AUTOSAR XML (schema 4-0-3)
package /CalibrationComponents
  parameter sw component type SOCR: data-type-mapping=[SOCR_CodeDataTypeMappingsSet, WorkingDataTypeMappingsSet]
    provide port SOCR_Pport: provided-interface=SOCR_if
      provided-com-specs:
        init-value=SOCR_Pport_KaSOCR_Ah_OvrdValue_CellCapacityCharge:96 x 55, parameter=KaSOCR_Ah_OvrdValue_CellCapacityCharge
        init-value=SOCR_Pport_KaSOCR_Ah_OvrdValue_CellCapacityDischarge:96 x 55, parameter=KaSOCR_Ah_OvrdValue_CellCapacityDischarge
        init-value=SOCR_Pport_KaSOCR_Pct_OvrdValue_CellSOCArray_new:96 x 100, parameter=KaSOCR_Pct_OvrdValue_CellSOCArray_new
        init-value=SOCR_Pport_KaSOCR_Pct_SOCini:96 x 95, parameter=KaSOCR_Pct_SOCini
        init-value=55, parameter=KeSOCR_Ah_BatteryCellsCap
        init-value=0, parameter=KeSOCR_Ah_MinCellCapacityCharge_Val
        init-value=0, parameter=KeSOCR_Ah_MinCellCapacityDischarge_Val
        init-value=55, parameter=KeSOCR_Ah_OvrdValue_BatteryPackCapacity
        init-value=55, parameter=KeSOCR_Ah_PackCapacityCharge_MaxVal
        init-value=55, parameter=KeSOCR_Ah_PackCapacityCharge_Val
        init-value=0, parameter=KeSOCR_Ah_PackCapacityCharge_minVal
        init-value=55, parameter=KeSOCR_Ah_PackCapacityDischarge_MaxVal
        init-value=55, parameter=KeSOCR_Ah_PackCapacityDischarge_Val
        init-value=0, parameter=KeSOCR_Ah_PackCapacityDischarge_minVal
        init-value=1, parameter=KeSOCR_Cnt_NumberOfCellParal
        init-value=0.019999999552965164, parameter=KeSOCR_I_CoseToZero
        init-value=0, parameter=KeSOCR_I_CoulombsCSC
        init-value=16.299999237060547, parameter=KeSOCR_I_CurrForCalcTTC_NoCharge
        init-value=3, parameter=KeSOCR_I_LowCurrent
        init-value=1, parameter=KeSOCR_I_SOCFixLowCurrent
        init-value=1, parameter=KeSOCR_I_ThrshldCorrSOCConvrg
        init-value=2, parameter=KeSOCR_I_ThrshldLowCurrent
        init-value=1, parameter=KeSOCR_I_ThrshldSOCCorrection_DE
        init-value=0.20000000298023224, parameter=KeSOCR_I_ThrshldZeroCurrent
        init-value=2, parameter=KeSOCR_Pct_AC_ChgPctCoeff
        init-value=0.10000000149011612, parameter=KeSOCR_Pct_CloseToZeroThreshold
        init-value=0, parameter=KeSOCR_Pct_CorrectedPackSOC_Val
        init-value=95, parameter=KeSOCR_Pct_CorrectedPackSOC_ini
        init-value=95.05000305175781, parameter=KeSOCR_Pct_CorrectedScaledSOC_ToCAN
        init-value=100.05000305175781, parameter=KeSOCR_Pct_CustomerPackSOC_MaxVal
        init-value=0, parameter=KeSOCR_Pct_CustomerPackSOC_Val
        init-value=0, parameter=KeSOCR_Pct_CustomerPackSOC_minVal
        init-value=100.05000305175781, parameter=KeSOCR_Pct_CustomerRealScaledSOC_ToCAN
        init-value=0, parameter=KeSOCR_Pct_DispSOC_Val
        init-value=95.05000305175781, parameter=KeSOCR_Pct_DisplayPackSOC_MaxVal
        init-value=95, parameter=KeSOCR_Pct_DisplayPackSOC_ini
        init-value=0, parameter=KeSOCR_Pct_DisplayPackSOC_minVal
        init-value=21.200000762939453, parameter=KeSOCR_Pct_LowSOC1_Reset
        init-value=20, parameter=KeSOCR_Pct_LowSOC1_Set
        init-value=16, parameter=KeSOCR_Pct_LowSOC2_Reset
        init-value=15, parameter=KeSOCR_Pct_LowSOC2_Set
        init-value=10, parameter=KeSOCR_Pct_LowSOC3_Reset
        init-value=8, parameter=KeSOCR_Pct_LowSOC3_Set
        init-value=0.6149818301200867, parameter=KeSOCR_Pct_MaxBalDrain
        init-value=94.9000015258789, parameter=KeSOCR_Pct_MaxSOCBeforeVCU_ChrgComplete
        init-value=0.01729624904692173, parameter=KeSOCR_Pct_MaxSlewRateLimitPer100msCorrSOC
        init-value=100, parameter=KeSOCR_Pct_OvrdValue_BatteryPackSOC
        init-value=100, parameter=KeSOCR_Pct_OvrdValue_DisplayPackSOC
        init-value=100, parameter=KeSOCR_Pct_OvrdValue_MaxSOC
        init-value=0, parameter=KeSOCR_Pct_OvrdValue_MinSOC
        init-value=0, parameter=KeSOCR_Pct_PackSOCDiff_Val
        init-value=0, parameter=KeSOCR_Pct_PackSOCDiff_ini
        init-value=1, parameter=KeSOCR_Pct_SOCChangeThreshold
        init-value=5, parameter=KeSOCR_Pct_SOCJumpWarn_Reset
        init-value=5, parameter=KeSOCR_Pct_SOCJumpWarn_Set
        init-value=95.05000305175781, parameter=KeSOCR_Pct_SOCOverWarn_Reset
        init-value=96, parameter=KeSOCR_Pct_SOCOverWarn_Set
        init-value=50, parameter=KeSOCR_Pct_SOC_SetPointUDS31010F15
        init-value=93, parameter=KeSOCR_Pct_SOC_ThresholdTTC
        init-value=2, parameter=KeSOCR_Pct_SlewRateLimitFbackDriving
        init-value=0.0016666667070239782, parameter=KeSOCR_Pct_SlewRateLimitPer100msAC
        init-value=0.008648124523460865, parameter=KeSOCR_Pct_SlewRateLimitPer100msCorrSOC
        init-value=0.0047222222201526165, parameter=KeSOCR_Pct_SlewRateLimitPer100msDC
        init-value=0.008648124523460865, parameter=KeSOCR_Pct_SlewRateLimitPer100msDriving
        init-value=30, parameter=KeSOCR_Pct_ThrshldCorrSOC
        init-value=0, parameter=KeSOCR_Pct_TsigBatteryPackSOC_Val
        init-value=37.5, parameter=KeSOCR_R_CSCBalancingR
        init-value=18, parameter=KeSOCR_T_HighTemprChgEnd_DC
        init-value=4.25, parameter=KeSOCR_U_100PctVoltage
        init-value=4.171000003814697, parameter=KeSOCR_U_CloseToEndOfCharge_AC
        init-value=4.184999942779541, parameter=KeSOCR_U_CloseToEndOfCharge_DC_1
        init-value=4.215000152587891, parameter=KeSOCR_U_CloseToEndOfCharge_DC_2
        init-value=4.179999828338623, parameter=KeSOCR_U_FullSOCVoltage_Reset
        init-value=4.179999828338623, parameter=KeSOCR_U_FullSOCVoltage_Set
        init-value=4.17549991607666, parameter=KeSOCR_U_TTC_StrategyThrshld
        init-value=1, parameter=KeSOCR_k_AccelCoeffAC_ChgSteadySt
        init-value=-8, parameter=KeSOCR_k_Coeff1_AC
        init-value=-5.714285850524902, parameter=KeSOCR_k_Coeff1_DC
        init-value=1.7999999523162842, parameter=KeSOCR_k_Coeff2_AC
        init-value=1.2857142686843872, parameter=KeSOCR_k_Coeff2_DC
        init-value=4.171000003814697, parameter=KeSOCR_k_CoeffBias
        init-value=0, parameter=KeSOCR_k_CoeffTMax
        init-value=0, parameter=KeSOCR_k_CoeffTMin
        init-value=5, parameter=KeSOCR_k_ContractDiffCorrSOC
        init-value=0.5, parameter=KeSOCR_k_ContractionCoeff
        init-value=0.550000011920929, parameter=KeSOCR_k_DutyCycleCompensation
        init-value=7, parameter=KeSOCR_k_MaxAccelCoeffAC_Chg
        init-value=300, parameter=KeSOCR_k_NumOf100msIn30Sec
        init-value=240, parameter=KeSOCR_min_InitTTC
        init-value=8, parameter=KeSOCR_min_TTC_Offset
        init-value=60, parameter=KeSOCR_min_TimeToCharge_Val
        init-value=5.5, parameter=KeSOCR_q_NomAccuCoulombs100ms
        init-value=0, parameter=KeSOCR_q_TsigAccuCoulombs_Val
        init-value=99.7300033569336, parameter=KeSOCR_r_CoulombEfficiency
        init-value=1, parameter=KeSOCR_r_RCGain_DE
        init-value=27.397258758544922, parameter=KeSOCR_r_SOCGainScale_DE
        init-value=0.0005553960800170898, parameter=KeSOCR_r_SOCGain_DE
        init-value=27.396728515625, parameter=KeSOCR_r_maxSOCGain_DE
        init-value=1, parameter=KeSOCR_t_FullSOCVoltage_Timer
        init-value=1, parameter=KeSOCR_t_LowSOC_DTCTimer
        init-value=10, parameter=KeSOCR_t_SOCJumpWarn_DTCTimer
        init-value=1, parameter=KeSOCR_t_SOCOverWarn_DTCTimer
        init-value=0.10000000149011612, parameter=KeSOCR_t_SR_SOC
        init-value=4, parameter=KeSOCR_Cnt_CalcInitSOCWithDefaultVals
        init-value=9, parameter=KeSOCR_k_ExtendNsamplesAck
        init-value=9, parameter=KeSOCR_k_ExtendSaveToExtEEP
        init-value=20, parameter=KeSOCR_n_DebncCloseToEndOfCharge
        init-value=5, parameter=KeSOCR_n_DebncDoSlewRateCorrSOC
        init-value=599, parameter=KeSOCR_n_Num100msInOneMinLess1
        init-value=200, parameter=KeSOCR_n_vMinDebounceTime_DE
        init-value=0, parameter=KeSOCR_b_CorrectedPackSOC_Ctrl
        init-value=0, parameter=KeSOCR_b_CustomerPackSOC_Ctrl
        init-value=0, parameter=KeSOCR_b_DispSOC_En
        init-value=0, parameter=KeSOCR_b_MinCellCapacityCharge_Ctrl
        init-value=0, parameter=KeSOCR_b_MinCellCapacityDischarge_Ctrl
        init-value=0, parameter=KeSOCR_b_NVMEnable_CellSOC_ini
        init-value=0, parameter=KeSOCR_b_OCV_Disable
        init-value=0, parameter=KeSOCR_b_OvrdCond_AccuCoulombsReset
        init-value=0, parameter=KeSOCR_b_OvrdCond_BatteryPackCapacity
        init-value=0, parameter=KeSOCR_b_OvrdCond_BatteryPackSOC
        init-value=0, parameter=KeSOCR_b_OvrdCond_CellCapacityCharge
        init-value=0, parameter=KeSOCR_b_OvrdCond_CellCapacityDischarge
        init-value=0, parameter=KeSOCR_b_OvrdCond_CellSOCArray_new
        init-value=0, parameter=KeSOCR_b_OvrdCond_DisplayPackSOC
        init-value=0, parameter=KeSOCR_b_OvrdCond_MaxSOC
        init-value=0, parameter=KeSOCR_b_OvrdCond_MinSOC
        init-value=0, parameter=KeSOCR_b_OvrdValue_AccuCoulombsReset
        init-value=0, parameter=KeSOCR_b_PackCapacityCharge_En
        init-value=0, parameter=KeSOCR_b_PackCapacityDischarge_En
        init-value=0, parameter=KeSOCR_b_PackSOCDiff_Ctrl
        init-value=0, parameter=KeSOCR_b_SOCJumpWarn_Rank_CAN_En
        init-value=0, parameter=KeSOCR_b_SOCJumpWarn_flt_En
        init-value=0, parameter=KeSOCR_b_SOCLow_Rank_CAN_En
        init-value=0, parameter=KeSOCR_b_SOCOverWarn_Rank_CAN_En
        init-value=0, parameter=KeSOCR_b_SOCOverWarn_flt_En
        init-value=0, parameter=KeSOCR_b_SOC_SetpointOverrideAck_Ctrl
        init-value=0, parameter=KeSOCR_b_SOC_SetpointOverrideAck_Val
        init-value=0, parameter=KeSOCR_b_SOC_low{1..3}_flt_En
        init-value=0, parameter=KeSOCR_b_SaveSOCInExtEEP_Ctrl
        init-value=0, parameter=KeSOCR_b_SaveSOCInExtEEP_Val
        init-value=0, parameter=KeSOCR_b_TimeToCharge_Ctrl
        init-value=0, parameter=KeSOCR_b_TsigAccuCoulombs_Ctrl
        init-value=0, parameter=KeSOCR_b_TsigBatteryPackSOC_Ctrl
        init-value=1, parameter=KeSOCR_b_enable_DE
        init-value=0, parameter=KeSOCR_k_SOCJumpWarn_Rank_CAN_Val
        init-value=0, parameter=KeSOCR_k_SOCJumpWarn_flt_Val
        init-value=0, parameter=KeSOCR_k_SOCLow_Rank_CAN_Val
        init-value=0, parameter=KeSOCR_k_SOCOverWarn_Rank_CAN_Val
        init-value=0, parameter=KeSOCR_k_SOCOverWarn_flt_Val
        init-value=0, parameter=KeSOCR_k_SOC_low{1..3}_flt_Val
package /SOCR_Code_pkg/SOCR_Code_swc
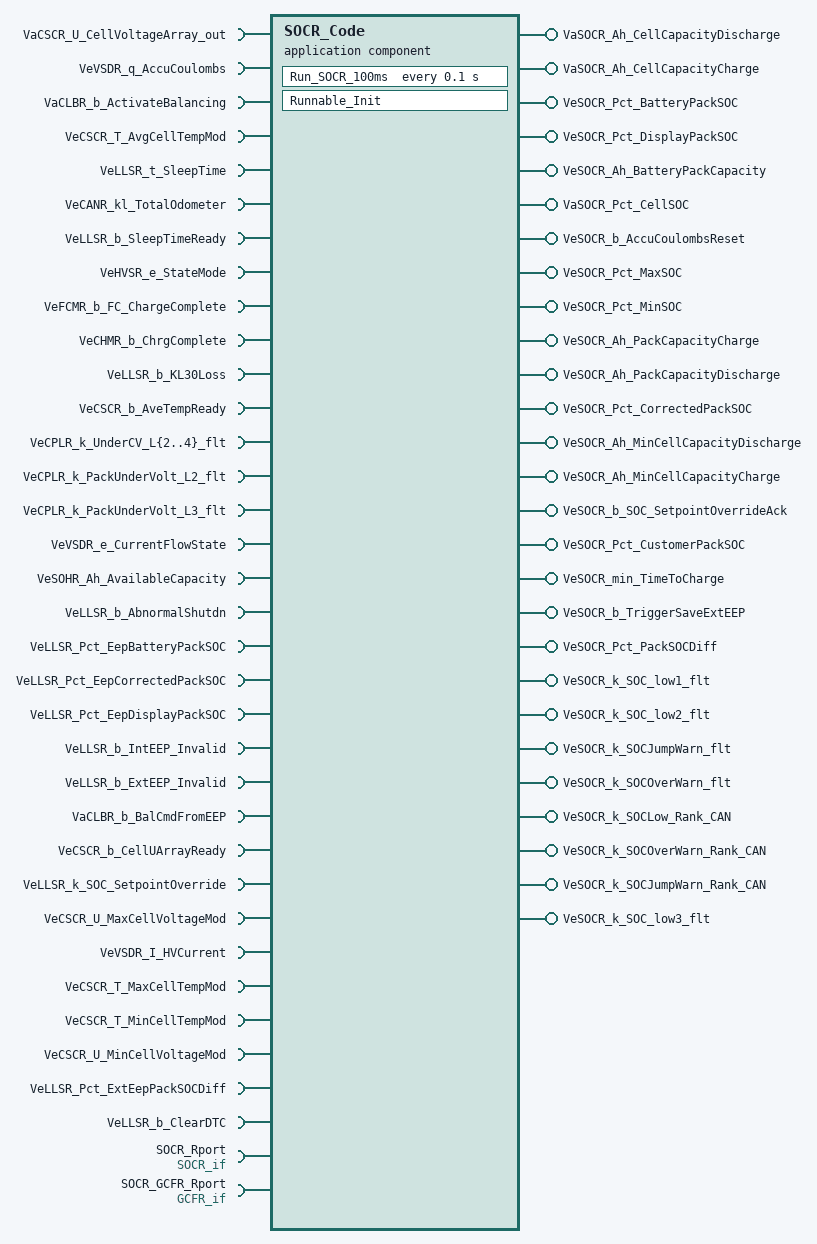
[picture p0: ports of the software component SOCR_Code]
  application sw component type SOCR_Code
    35 x require port:
      VaCSCR_U_CellVoltageArray_out: nonqueued-receiver-com-spec{data-element=VaCSCR_U_CellVoltageArray_out, init-value=96 x 0}, required-interface=VaCSCR_U_CellVoltageArray_out
      VeVSDR_q_AccuCoulombs: nonqueued-receiver-com-spec{data-element=VeVSDR_q_AccuCoulombs, init-value=0}, required-interface=VeVSDR_q_AccuCoulombs
      VaCLBR_b_ActivateBalancing: nonqueued-receiver-com-spec{data-element=VaCLBR_b_ActivateBalancing, init-value=96 x 0}, required-interface=VaCLBR_b_ActivateBalancing
      VeCSCR_T_AvgCellTempMod: nonqueued-receiver-com-spec{data-element=VeCSCR_T_AvgCellTempMod, init-value=0}, required-interface=VeCSCR_T_AvgCellTempMod
      VeLLSR_t_SleepTime: nonqueued-receiver-com-spec{data-element=VeLLSR_t_SleepTime, init-value=0}, required-interface=VeLLSR_t_SleepTime
      VeCANR_kl_TotalOdometer: nonqueued-receiver-com-spec{data-element=VeCANR_kl_TotalOdometer, init-value=0}, required-interface=VeCANR_kl_TotalOdometer
      VeLLSR_b_SleepTimeReady: nonqueued-receiver-com-spec{data-element=VeLLSR_b_SleepTimeReady, init-value=0}, required-interface=VeLLSR_b_SleepTimeReady
      VeHVSR_e_StateMode: nonqueued-receiver-com-spec{data-element=VeHVSR_e_StateMode, init-value=CeHVSR_e_StateModeReserved}, required-interface=VeHVSR_e_StateMode
      VeFCMR_b_FC_ChargeComplete: nonqueued-receiver-com-spec{data-element=VeFCMR_b_FC_ChargeComplete, init-value=0}, required-interface=VeFCMR_b_FC_ChargeComplete
      VeCHMR_b_ChrgComplete: nonqueued-receiver-com-spec{data-element=VeCHMR_b_ChrgComplete, init-value=0}, required-interface=VeCHMR_b_ChrgComplete
      VeLLSR_b_KL30Loss: nonqueued-receiver-com-spec{data-element=VeLLSR_b_KL30Loss, init-value=0}, required-interface=VeLLSR_b_KL30Loss
      VeCSCR_b_AveTempReady: nonqueued-receiver-com-spec{data-element=VeCSCR_b_AveTempReady, init-value=0}, required-interface=VeCSCR_b_AveTempReady
      VeCPLR_k_UnderCV_L{2..4}_flt: nonqueued-receiver-com-spec{data-element=VeCPLR_k_UnderCV_L{2..4}_flt, init-value=0}, required-interface=VeCPLR_k_UnderCV_L{2..4}_flt
      VeCPLR_k_PackUnderVolt_L2_flt: nonqueued-receiver-com-spec{data-element=VeCPLR_k_PackUnderVolt_L2_flt, init-value=0}, required-interface=VeCPLR_k_PackUnderVolt_L2_flt
      VeCPLR_k_PackUnderVolt_L3_flt: nonqueued-receiver-com-spec{data-element=VeCPLR_k_PackUnderVolt_L3_flt, init-value=0}, required-interface=VeCPLR_k_PackUnderVolt_L3_flt
      VeVSDR_e_CurrentFlowState: nonqueued-receiver-com-spec{data-element=VeVSDR_e_CurrentFlowState, init-value=CeVSDR_e_CurFlowStateInit}, required-interface=VeVSDR_e_CurrentFlowState
      VeSOHR_Ah_AvailableCapacity: nonqueued-receiver-com-spec{data-element=VeSOHR_Ah_AvailableCapacity, init-value=0}, required-interface=VeSOHR_Ah_AvailableCapacity
      VeLLSR_b_AbnormalShutdn: nonqueued-receiver-com-spec{data-element=VeLLSR_b_AbnormalShutdn, init-value=0}, required-interface=VeLLSR_b_AbnormalShutdn
      VeLLSR_Pct_EepBatteryPackSOC: nonqueued-receiver-com-spec{data-element=VeLLSR_Pct_EepBatteryPackSOC, init-value=0}, required-interface=VeLLSR_Pct_EepBatteryPackSOC
      VeLLSR_Pct_EepCorrectedPackSOC: nonqueued-receiver-com-spec{data-element=VeLLSR_Pct_EepCorrectedPackSOC, init-value=0}, required-interface=VeLLSR_Pct_EepCorrectedPackSOC
      VeLLSR_Pct_EepDisplayPackSOC: nonqueued-receiver-com-spec{data-element=VeLLSR_Pct_EepDisplayPackSOC, init-value=0}, required-interface=VeLLSR_Pct_EepDisplayPackSOC
      VeLLSR_b_IntEEP_Invalid: nonqueued-receiver-com-spec{data-element=VeLLSR_b_IntEEP_Invalid, init-value=0}, required-interface=VeLLSR_b_IntEEP_Invalid
      VeLLSR_b_ExtEEP_Invalid: nonqueued-receiver-com-spec{data-element=VeLLSR_b_ExtEEP_Invalid, init-value=0}, required-interface=VeLLSR_b_ExtEEP_Invalid
      VaCLBR_b_BalCmdFromEEP: nonqueued-receiver-com-spec{data-element=VaCLBR_b_BalCmdFromEEP, init-value=96 x 0}, required-interface=VaCLBR_b_BalCmdFromEEP
      VeCSCR_b_CellUArrayReady: nonqueued-receiver-com-spec{data-element=VeCSCR_b_CellUArrayReady, init-value=0}, required-interface=VeCSCR_b_CellUArrayReady
      VeLLSR_k_SOC_SetpointOverride: nonqueued-receiver-com-spec{data-element=VeLLSR_k_SOC_SetpointOverride, init-value=0}, required-interface=VeLLSR_k_SOC_SetpointOverride
      VeCSCR_U_MaxCellVoltageMod: nonqueued-receiver-com-spec{data-element=VeCSCR_U_MaxCellVoltageMod, init-value=0}, required-interface=VeCSCR_U_MaxCellVoltageMod
      VeVSDR_I_HVCurrent: nonqueued-receiver-com-spec{data-element=VeVSDR_I_HVCurrent, init-value=0}, required-interface=VeVSDR_I_HVCurrent
      VeCSCR_T_MaxCellTempMod: nonqueued-receiver-com-spec{data-element=VeCSCR_T_MaxCellTempMod, init-value=0}, required-interface=VeCSCR_T_MaxCellTempMod
      VeCSCR_T_MinCellTempMod: nonqueued-receiver-com-spec{data-element=VeCSCR_T_MinCellTempMod, init-value=0}, required-interface=VeCSCR_T_MinCellTempMod
      VeCSCR_U_MinCellVoltageMod: nonqueued-receiver-com-spec{data-element=VeCSCR_U_MinCellVoltageMod, init-value=0}, required-interface=VeCSCR_U_MinCellVoltageMod
      VeLLSR_Pct_ExtEepPackSOCDiff: nonqueued-receiver-com-spec{data-element=VeLLSR_Pct_ExtEepPackSOCDiff, init-value=0}, required-interface=VeLLSR_Pct_ExtEepPackSOCDiff
      VeLLSR_b_ClearDTC: nonqueued-receiver-com-spec{data-element=VeLLSR_b_ClearDTC, init-value=0}, required-interface=VeLLSR_b_ClearDTC
    27 x provide port:
      VaSOCR_Ah_CellCapacityDischarge: nonqueued-sender-com-spec{data-element=VaSOCR_Ah_CellCapacityDischarge, init-value=96 x 0}, provided-interface=VaSOCR_Ah_CellCapacityDischarge
      VaSOCR_Ah_CellCapacityCharge: nonqueued-sender-com-spec{data-element=VaSOCR_Ah_CellCapacityCharge, init-value=96 x 0}, provided-interface=VaSOCR_Ah_CellCapacityCharge
      VeSOCR_Pct_BatteryPackSOC: nonqueued-sender-com-spec{data-element=VeSOCR_Pct_BatteryPackSOC, init-value=0}, provided-interface=VeSOCR_Pct_BatteryPackSOC
      VeSOCR_Pct_DisplayPackSOC: nonqueued-sender-com-spec{data-element=VeSOCR_Pct_DisplayPackSOC, init-value=0}, provided-interface=VeSOCR_Pct_DisplayPackSOC
      VeSOCR_Ah_BatteryPackCapacity: nonqueued-sender-com-spec{data-element=VeSOCR_Ah_BatteryPackCapacity, init-value=0}, provided-interface=VeSOCR_Ah_BatteryPackCapacity
      VaSOCR_Pct_CellSOC: nonqueued-sender-com-spec{data-element=VaSOCR_Pct_CellSOC, init-value=96 x 0}, provided-interface=VaSOCR_Pct_CellSOC
      VeSOCR_b_AccuCoulombsReset: nonqueued-sender-com-spec{data-element=VeSOCR_b_AccuCoulombsReset, init-value=0}, provided-interface=VeSOCR_b_AccuCoulombsReset
      VeSOCR_Pct_MaxSOC: nonqueued-sender-com-spec{data-element=VeSOCR_Pct_MaxSOC, init-value=0}, provided-interface=VeSOCR_Pct_MaxSOC
      VeSOCR_Pct_MinSOC: nonqueued-sender-com-spec{data-element=VeSOCR_Pct_MinSOC, init-value=0}, provided-interface=VeSOCR_Pct_MinSOC
      VeSOCR_Ah_PackCapacityCharge: nonqueued-sender-com-spec{data-element=VeSOCR_Ah_PackCapacityCharge, init-value=0}, provided-interface=VeSOCR_Ah_PackCapacityCharge
      VeSOCR_Ah_PackCapacityDischarge: nonqueued-sender-com-spec{data-element=VeSOCR_Ah_PackCapacityDischarge, init-value=0}, provided-interface=VeSOCR_Ah_PackCapacityDischarge
      VeSOCR_Pct_CorrectedPackSOC: nonqueued-sender-com-spec{data-element=VeSOCR_Pct_CorrectedPackSOC, init-value=0}, provided-interface=VeSOCR_Pct_CorrectedPackSOC
      VeSOCR_Ah_MinCellCapacityDischarge: nonqueued-sender-com-spec{data-element=VeSOCR_Ah_MinCellCapacityDischarge, init-value=0}, provided-interface=VeSOCR_Ah_MinCellCapacityDischarge
      VeSOCR_Ah_MinCellCapacityCharge: nonqueued-sender-com-spec{data-element=VeSOCR_Ah_MinCellCapacityCharge, init-value=0}, provided-interface=VeSOCR_Ah_MinCellCapacityCharge
      VeSOCR_b_SOC_SetpointOverrideAck: nonqueued-sender-com-spec{data-element=VeSOCR_b_SOC_SetpointOverrideAck, init-value=0}, provided-interface=VeSOCR_b_SOC_SetpointOverrideAck
      VeSOCR_Pct_CustomerPackSOC: nonqueued-sender-com-spec{data-element=VeSOCR_Pct_CustomerPackSOC, init-value=0}, provided-interface=VeSOCR_Pct_CustomerPackSOC
      VeSOCR_min_TimeToCharge: nonqueued-sender-com-spec{data-element=VeSOCR_min_TimeToCharge, init-value=0}, provided-interface=VeSOCR_min_TimeToCharge
      VeSOCR_b_TriggerSaveExtEEP: nonqueued-sender-com-spec{data-element=VeSOCR_b_TriggerSaveExtEEP, init-value=0}, provided-interface=VeSOCR_b_TriggerSaveExtEEP
      VeSOCR_Pct_PackSOCDiff: nonqueued-sender-com-spec{data-element=VeSOCR_Pct_PackSOCDiff, init-value=0}, provided-interface=VeSOCR_Pct_PackSOCDiff
      VeSOCR_k_SOC_low1_flt: nonqueued-sender-com-spec{data-element=VeSOCR_k_SOC_low1_flt, init-value=0}, provided-interface=VeSOCR_k_SOC_low1_flt
      VeSOCR_k_SOC_low2_flt: nonqueued-sender-com-spec{data-element=VeSOCR_k_SOC_low2_flt, init-value=0}, provided-interface=VeSOCR_k_SOC_low2_flt
      VeSOCR_k_SOCJumpWarn_flt: nonqueued-sender-com-spec{data-element=VeSOCR_k_SOCJumpWarn_flt, init-value=0}, provided-interface=VeSOCR_k_SOCJumpWarn_flt
      VeSOCR_k_SOCOverWarn_flt: nonqueued-sender-com-spec{data-element=VeSOCR_k_SOCOverWarn_flt, init-value=0}, provided-interface=VeSOCR_k_SOCOverWarn_flt
      VeSOCR_k_SOCLow_Rank_CAN: nonqueued-sender-com-spec{data-element=VeSOCR_k_SOCLow_Rank_CAN, init-value=0}, provided-interface=VeSOCR_k_SOCLow_Rank_CAN
      VeSOCR_k_SOCOverWarn_Rank_CAN: nonqueued-sender-com-spec{data-element=VeSOCR_k_SOCOverWarn_Rank_CAN, init-value=0}, provided-interface=VeSOCR_k_SOCOverWarn_Rank_CAN
      VeSOCR_k_SOCJumpWarn_Rank_CAN: nonqueued-sender-com-spec{data-element=VeSOCR_k_SOCJumpWarn_Rank_CAN, init-value=0}, provided-interface=VeSOCR_k_SOCJumpWarn_Rank_CAN
      VeSOCR_k_SOC_low3_flt: nonqueued-sender-com-spec{data-element=VeSOCR_k_SOC_low3_flt, init-value=0}, provided-interface=VeSOCR_k_SOC_low3_flt
    require port SOCR_Rport: required-interface=SOCR_if
    require port SOCR_GCFR_Rport: required-interface=GCFR_if
    behavior SOCR_Code: constant-value-mapping=SOCR_Code_datatype_AVS_MappingSet, data-type-mapping=[SOCR_CodeDataTypeMappingsSet, WorkingDataTypeMappingsSet], handle-termination-and-restart=NO-SUPPORT
      constant-memorys:
        5 x parameter data prototype, all with sw-calibration-access=READ-WRITE:
          CtSOCR_cmp_SOCOCV_mean: category=COM_AXIS, type=Appl_CtSOCR_cmp_SOCOCV_mean, init-value=constant-reference={short-label=CtSOCR_cmp_SOCOCV_mean, constant=CtSOCR_cmp_SOCOCV_mean}
          CxSOCR_cmp_SOCOCV_mean: category=COM_AXIS, type=Appl_CxSOCR_cmp_SOCOCV_mean, init-value=constant-reference={short-label=CxSOCR_cmp_SOCOCV_mean, constant=CxSOCR_cmp_SOCOCV_mean}
          CxSOCR_k_TrustFactorOCV: category=COM_AXIS, type=Appl_CxSOCR_k_TrustFactorOCV, init-value=constant-reference={short-label=CxSOCR_k_TrustFactorOCV, constant=CxSOCR_k_TrustFactorOCV}
          CzSOCR_cmp_SOCOCV_mean_data: category=MAP, type=Appl_CzSOCR_cmp_SOCOCV_mean_data, init-value=constant-reference={short-label=CzSOCR_cmp_SOCOCV_mean_data, constant=CzSOCR_cmp_SOCOCV_mean_data}
          CzSOCR_k_TrustFactorOCV_data: category=CURVE, type=Appl_CzSOCR_k_TrustFactorOCV_data, init-value=constant-reference={short-label=CzSOCR_k_TrustFactorOCV_data, constant=CzSOCR_k_TrustFactorOCV_data}
      5 x exclusive area:
        EA_NeSOCR_Pct_DisplayPackSOC
        EA_NaSOCR_Pct_CellSOC
        EA_NeSOCR_Pct_CorrectedPackSOC
        EA_NeSOCR_Pct_PackSOCDiff
        EA_NeSOCR_b_NVMEnable_CellSOC
      static-memorys:
        9 x data, all with sw-calibration-access=READ-ONLY:
          VeSOCR_Pct_TsigCorrSOC_Prev: category=VALUE, type=Float
          VeSOCR_Pct_TsigDeltaSOC_Up: category=VALUE, type=Float
          VeSOCR_Pct_sloc_DE: category=VALUE, type=Float
          VeSOCR_k_TsigCurrentCrate: category=VALUE, type=Float
          VeSOCR_Ah_TsigContractedCapacity: category=VALUE, type=Float
          VeSOCR_Pct_TsigDispSOC: category=VALUE, type=Float
          VeSOCR_b_TsigChargeEndActive_Prev: category=BOOLEAN, type=Boolean
          VeSOCR_b_TsigAC_ChgEngActiveCond1: category=BOOLEAN, type=Boolean
          VeSOCR_b_TeigGT18DegC: category=BOOLEAN, type=Boolean
      timing event Event_Run_SOCR_100ms: start-on-event=Run_SOCR_100ms, period=0.1
      5 x per instance memory:
        NeSOCR_Pct_DisplayPackSOC: implementation-data-type=Float, type=NeSOCR_Pct_DisplayPackSOC_Float, type-definition=Float
        NaSOCR_Pct_CellSOC: implementation-data-type=rt_Array_Float_96, type=NaSOCR_Pct_CellSOC_rt_Array_Float_96, type-definition=rt_Array_Float_96
        NeSOCR_Pct_CorrectedPackSOC: implementation-data-type=Float, type=NeSOCR_Pct_CorrectedPackSOC_Float, type-definition=Float
        NeSOCR_Pct_PackSOCDiff: implementation-data-type=Float, type=NeSOCR_Pct_PackSOCDiff_Float, type-definition=Float
        NeSOCR_b_NVMEnable_CellSOC: implementation-data-type=Boolean, type=NeSOCR_b_NVMEnable_CellSOC_Boolean, type-definition=Boolean
      runnable Runnable_Init: symbol=SOCR_Code_Init
      runnable Run_SOCR_100ms: runs-inside-exclusive-area=[EA_NaSOCR_Pct_CellSOC, EA_NeSOCR_Pct_CorrectedPackSOC, EA_NeSOCR_Pct_DisplayPackSOC, EA_NeSOCR_Pct_PackSOCDiff]
        data-read-access:
          35 x access:
            IN_VaCLBR_b_ActivateBalancing_VaCLBR_b_ActivateBalancing: accessed-variable=VaCLBR_b_ActivateBalancing.VaCLBR_b_ActivateBalancing
            IN_VaCLBR_b_BalCmdFromEEP_VaCLBR_b_BalCmdFromEEP: accessed-variable=VaCLBR_b_BalCmdFromEEP.VaCLBR_b_BalCmdFromEEP
            IN_VaCSCR_U_CellVoltageArray_out_VaCSCR_U_CellVoltageArray_out: accessed-variable=VaCSCR_U_CellVoltageArray_out.VaCSCR_U_CellVoltageArray_out
            IN_VeCANR_kl_TotalOdometer_VeCANR_kl_TotalOdometer: accessed-variable=VeCANR_kl_TotalOdometer.VeCANR_kl_TotalOdometer
            IN_VeCHMR_b_ChrgComplete_VeCHMR_b_ChrgComplete: accessed-variable=VeCHMR_b_ChrgComplete.VeCHMR_b_ChrgComplete
            IN_VeCPLR_k_PackUnderVolt_L2_flt_VeCPLR_k_PackUnderVolt_L2_flt: accessed-variable=VeCPLR_k_PackUnderVolt_L2_flt.VeCPLR_k_PackUnderVolt_L2_flt
            IN_VeCPLR_k_PackUnderVolt_L3_flt_VeCPLR_k_PackUnderVolt_L3_flt: accessed-variable=VeCPLR_k_PackUnderVolt_L3_flt.VeCPLR_k_PackUnderVolt_L3_flt
            IN_VeCPLR_k_UnderCV_L{2..4}_flt_VeCPLR_k_UnderCV_L{2..4}_flt: accessed-variable=VeCPLR_k_UnderCV_L{2..4}_flt.VeCPLR_k_UnderCV_L{2..4}_flt
            IN_VeCSCR_T_AvgCellTempMod_VeCSCR_T_AvgCellTempMod: accessed-variable=VeCSCR_T_AvgCellTempMod.VeCSCR_T_AvgCellTempMod
            IN_VeCSCR_T_MaxCellTempMod_VeCSCR_T_MaxCellTempMod: accessed-variable=VeCSCR_T_MaxCellTempMod.VeCSCR_T_MaxCellTempMod
            IN_VeCSCR_T_MinCellTempMod_VeCSCR_T_MinCellTempMod: accessed-variable=VeCSCR_T_MinCellTempMod.VeCSCR_T_MinCellTempMod
            IN_VeCSCR_U_MaxCellVoltageMod_VeCSCR_U_MaxCellVoltageMod: accessed-variable=VeCSCR_U_MaxCellVoltageMod.VeCSCR_U_MaxCellVoltageMod
            IN_VeCSCR_U_MinCellVoltageMod_VeCSCR_U_MinCellVoltageMod: accessed-variable=VeCSCR_U_MinCellVoltageMod.VeCSCR_U_MinCellVoltageMod
            IN_VeCSCR_b_AveTempReady_VeCSCR_b_AveTempReady: accessed-variable=VeCSCR_b_AveTempReady.VeCSCR_b_AveTempReady
            IN_VeCSCR_b_CellUArrayReady_VeCSCR_b_CellUArrayReady: accessed-variable=VeCSCR_b_CellUArrayReady.VeCSCR_b_CellUArrayReady
            IN_VeFCMR_b_FC_ChargeComplete_VeFCMR_b_FC_ChargeComplete: accessed-variable=VeFCMR_b_FC_ChargeComplete.VeFCMR_b_FC_ChargeComplete
            IN_VeHVSR_e_StateMode_VeHVSR_e_StateMode: accessed-variable=VeHVSR_e_StateMode.VeHVSR_e_StateMode
            IN_VeLLSR_Pct_EepBatteryPackSOC_VeLLSR_Pct_EepBatteryPackSOC: accessed-variable=VeLLSR_Pct_EepBatteryPackSOC.VeLLSR_Pct_EepBatteryPackSOC
            IN_VeLLSR_Pct_EepCorrectedPackSOC_VeLLSR_Pct_78680fe8bbbb4fa6: accessed-variable=VeLLSR_Pct_EepCorrectedPackSOC.VeLLSR_Pct_EepCorrectedPackSOC
            IN_VeLLSR_Pct_EepDisplayPackSOC_VeLLSR_Pct_EepDisplayPackSOC: accessed-variable=VeLLSR_Pct_EepDisplayPackSOC.VeLLSR_Pct_EepDisplayPackSOC
            IN_VeLLSR_Pct_ExtEepPackSOCDiff_VeLLSR_Pct_ExtEepPackSOCDiff: accessed-variable=VeLLSR_Pct_ExtEepPackSOCDiff.VeLLSR_Pct_ExtEepPackSOCDiff
            IN_VeLLSR_b_AbnormalShutdn_VeLLSR_b_AbnormalShutdn: accessed-variable=VeLLSR_b_AbnormalShutdn.VeLLSR_b_AbnormalShutdn
            IN_VeLLSR_b_ClearDTC_VeLLSR_b_ClearDTC: accessed-variable=VeLLSR_b_ClearDTC.VeLLSR_b_ClearDTC
            IN_VeLLSR_b_ExtEEP_Invalid_VeLLSR_b_ExtEEP_Invalid: accessed-variable=VeLLSR_b_ExtEEP_Invalid.VeLLSR_b_ExtEEP_Invalid
            IN_VeLLSR_b_IntEEP_Invalid_VeLLSR_b_IntEEP_Invalid: accessed-variable=VeLLSR_b_IntEEP_Invalid.VeLLSR_b_IntEEP_Invalid
            IN_VeLLSR_b_KL30Loss_VeLLSR_b_KL30Loss: accessed-variable=VeLLSR_b_KL30Loss.VeLLSR_b_KL30Loss
            IN_VeLLSR_b_SleepTimeReady_VeLLSR_b_SleepTimeReady: accessed-variable=VeLLSR_b_SleepTimeReady.VeLLSR_b_SleepTimeReady
            IN_VeLLSR_k_SOC_SetpointOverride_VeLLSR_k_SOC_SetpointOverride: accessed-variable=VeLLSR_k_SOC_SetpointOverride.VeLLSR_k_SOC_SetpointOverride
            IN_VeLLSR_t_SleepTime_VeLLSR_t_SleepTime: accessed-variable=VeLLSR_t_SleepTime.VeLLSR_t_SleepTime
            IN_VeSOHR_Ah_AvailableCapacity_VeSOHR_Ah_AvailableCapacity: accessed-variable=VeSOHR_Ah_AvailableCapacity.VeSOHR_Ah_AvailableCapacity
            IN_VeVSDR_I_HVCurrent_VeVSDR_I_HVCurrent: accessed-variable=VeVSDR_I_HVCurrent.VeVSDR_I_HVCurrent
            IN_VeVSDR_e_CurrentFlowState_VeVSDR_e_CurrentFlowState: accessed-variable=VeVSDR_e_CurrentFlowState.VeVSDR_e_CurrentFlowState
            IN_VeVSDR_q_AccuCoulombs_VeVSDR_q_AccuCoulombs: accessed-variable=VeVSDR_q_AccuCoulombs.VeVSDR_q_AccuCoulombs
        data-send-points:
          27 x access:
            OUT_VaSOCR_Ah_CellCapacityDischarge_VaSOCR_Ah_9f0788201dfffcdb: accessed-variable=VaSOCR_Ah_CellCapacityDischarge.VaSOCR_Ah_CellCapacityDischarge
            OUT_VaSOCR_Ah_CellCapacityCharge_VaSOCR_Ah_CellCapacityCharge: accessed-variable=VaSOCR_Ah_CellCapacityCharge.VaSOCR_Ah_CellCapacityCharge
            OUT_VeSOCR_Pct_BatteryPackSOC_VeSOCR_Pct_BatteryPackSOC: accessed-variable=VeSOCR_Pct_BatteryPackSOC.VeSOCR_Pct_BatteryPackSOC
            OUT_VeSOCR_Pct_DisplayPackSOC_VeSOCR_Pct_DisplayPackSOC: accessed-variable=VeSOCR_Pct_DisplayPackSOC.VeSOCR_Pct_DisplayPackSOC
            OUT_VeSOCR_Ah_BatteryPackCapacity_VeSOCR_Ah_B_64d076547a1a5e59: accessed-variable=VeSOCR_Ah_BatteryPackCapacity.VeSOCR_Ah_BatteryPackCapacity
            OUT_VaSOCR_Pct_CellSOC_VaSOCR_Pct_CellSOC: accessed-variable=VaSOCR_Pct_CellSOC.VaSOCR_Pct_CellSOC
            OUT_VeSOCR_b_AccuCoulombsReset_VeSOCR_b_AccuCoulombsReset: accessed-variable=VeSOCR_b_AccuCoulombsReset.VeSOCR_b_AccuCoulombsReset
            OUT_VeSOCR_Pct_MaxSOC_VeSOCR_Pct_MaxSOC: accessed-variable=VeSOCR_Pct_MaxSOC.VeSOCR_Pct_MaxSOC
            OUT_VeSOCR_Pct_MinSOC_VeSOCR_Pct_MinSOC: accessed-variable=VeSOCR_Pct_MinSOC.VeSOCR_Pct_MinSOC
            OUT_VeSOCR_Ah_PackCapacityCharge_VeSOCR_Ah_PackCapacityCharge: accessed-variable=VeSOCR_Ah_PackCapacityCharge.VeSOCR_Ah_PackCapacityCharge
            OUT_VeSOCR_Ah_PackCapacityDischarge_VeSOCR_Ah_b424ed4fcbd4c89c: accessed-variable=VeSOCR_Ah_PackCapacityDischarge.VeSOCR_Ah_PackCapacityDischarge
            OUT_VeSOCR_Pct_CorrectedPackSOC_VeSOCR_Pct_CorrectedPackSOC: accessed-variable=VeSOCR_Pct_CorrectedPackSOC.VeSOCR_Pct_CorrectedPackSOC
            OUT_VeSOCR_Ah_MinCellCapacityDischarge_VeSOCR_05f0974ae868165a: accessed-variable=VeSOCR_Ah_MinCellCapacityDischarge.VeSOCR_Ah_MinCellCapacityDischarge
            OUT_VeSOCR_Ah_MinCellCapacityCharge_VeSOCR_Ah_22a93fb67a1b616c: accessed-variable=VeSOCR_Ah_MinCellCapacityCharge.VeSOCR_Ah_MinCellCapacityCharge
            OUT_VeSOCR_b_SOC_SetpointOverrideAck_VeSOCR_b_01812133966270df: accessed-variable=VeSOCR_b_SOC_SetpointOverrideAck.VeSOCR_b_SOC_SetpointOverrideAck
            OUT_VeSOCR_Pct_CustomerPackSOC_VeSOCR_Pct_CustomerPackSOC: accessed-variable=VeSOCR_Pct_CustomerPackSOC.VeSOCR_Pct_CustomerPackSOC
            OUT_VeSOCR_min_TimeToCharge_VeSOCR_min_TimeToCharge: accessed-variable=VeSOCR_min_TimeToCharge.VeSOCR_min_TimeToCharge
            OUT_VeSOCR_b_TriggerSaveExtEEP_VeSOCR_b_TriggerSaveExtEEP: accessed-variable=VeSOCR_b_TriggerSaveExtEEP.VeSOCR_b_TriggerSaveExtEEP
            OUT_VeSOCR_Pct_PackSOCDiff_VeSOCR_Pct_PackSOCDiff: accessed-variable=VeSOCR_Pct_PackSOCDiff.VeSOCR_Pct_PackSOCDiff
            OUT_VeSOCR_k_SOC_low1_flt_VeSOCR_k_SOC_low1_flt: accessed-variable=VeSOCR_k_SOC_low1_flt.VeSOCR_k_SOC_low1_flt
            OUT_VeSOCR_k_SOC_low2_flt_VeSOCR_k_SOC_low2_flt: accessed-variable=VeSOCR_k_SOC_low2_flt.VeSOCR_k_SOC_low2_flt
            OUT_VeSOCR_k_SOCJumpWarn_flt_VeSOCR_k_SOCJumpWarn_flt: accessed-variable=VeSOCR_k_SOCJumpWarn_flt.VeSOCR_k_SOCJumpWarn_flt
            OUT_VeSOCR_k_SOCOverWarn_flt_VeSOCR_k_SOCOverWarn_flt: accessed-variable=VeSOCR_k_SOCOverWarn_flt.VeSOCR_k_SOCOverWarn_flt
            OUT_VeSOCR_k_SOCLow_Rank_CAN_VeSOCR_k_SOCLow_Rank_CAN: accessed-variable=VeSOCR_k_SOCLow_Rank_CAN.VeSOCR_k_SOCLow_Rank_CAN
            OUT_VeSOCR_k_SOCOverWarn_Rank_CAN_VeSOCR_k_SO_d9b7cf13d1b3d757: accessed-variable=VeSOCR_k_SOCOverWarn_Rank_CAN.VeSOCR_k_SOCOverWarn_Rank_CAN
            OUT_VeSOCR_k_SOCJumpWarn_Rank_CAN_VeSOCR_k_SO_3529c3c2435f5ceb: accessed-variable=VeSOCR_k_SOCJumpWarn_Rank_CAN.VeSOCR_k_SOCJumpWarn_Rank_CAN
            OUT_VeSOCR_k_SOC_low3_flt_VeSOCR_k_SOC_low3_flt: accessed-variable=VeSOCR_k_SOC_low3_flt.VeSOCR_k_SOC_low3_flt
        154 x parameter access:
          CALPRM_SOCR_Rport_KaSOCR_Ah_OvrdValue_CellCapacityCharge: accessed-parameter=SOCR_Rport.KaSOCR_Ah_OvrdValue_CellCapacityCharge
          CALPRM_SOCR_Rport_KaSOCR_Ah_OvrdValue_CellCapacityDischarge: accessed-parameter=SOCR_Rport.KaSOCR_Ah_OvrdValue_CellCapacityDischarge
          CALPRM_SOCR_Rport_KaSOCR_Pct_OvrdValue_CellSOCArray_new: accessed-parameter=SOCR_Rport.KaSOCR_Pct_OvrdValue_CellSOCArray_new
          CALPRM_SOCR_GCFR_Rport_KeGCFR_Cnt_NumberofCells: accessed-parameter=SOCR_GCFR_Rport.KeGCFR_Cnt_NumberofCells
          CALPRM_SOCR_Rport_KeSOCR_Ah_BatteryCellsCap: accessed-parameter=SOCR_Rport.KeSOCR_Ah_BatteryCellsCap
          CALPRM_SOCR_Rport_KeSOCR_Ah_MinCellCapacityCharge_Val: accessed-parameter=SOCR_Rport.KeSOCR_Ah_MinCellCapacityCharge_Val
          CALPRM_SOCR_Rport_KeSOCR_Ah_MinCellCapacityDischarge_Val: accessed-parameter=SOCR_Rport.KeSOCR_Ah_MinCellCapacityDischarge_Val
          CALPRM_SOCR_Rport_KeSOCR_Ah_OvrdValue_BatteryPackCapacity: accessed-parameter=SOCR_Rport.KeSOCR_Ah_OvrdValue_BatteryPackCapacity
          CALPRM_SOCR_Rport_KeSOCR_Ah_PackCapacityCharge_MaxVal: accessed-parameter=SOCR_Rport.KeSOCR_Ah_PackCapacityCharge_MaxVal
          CALPRM_SOCR_Rport_KeSOCR_Ah_PackCapacityCharge_Val: accessed-parameter=SOCR_Rport.KeSOCR_Ah_PackCapacityCharge_Val
          CALPRM_SOCR_Rport_KeSOCR_Ah_PackCapacityCharge_minVal: accessed-parameter=SOCR_Rport.KeSOCR_Ah_PackCapacityCharge_minVal
          CALPRM_SOCR_Rport_KeSOCR_Ah_PackCapacityDischarge_MaxVal: accessed-parameter=SOCR_Rport.KeSOCR_Ah_PackCapacityDischarge_MaxVal
          CALPRM_SOCR_Rport_KeSOCR_Ah_PackCapacityDischarge_Val: accessed-parameter=SOCR_Rport.KeSOCR_Ah_PackCapacityDischarge_Val
          CALPRM_SOCR_Rport_KeSOCR_Ah_PackCapacityDischarge_minVal: accessed-parameter=SOCR_Rport.KeSOCR_Ah_PackCapacityDischarge_minVal
          CALPRM_SOCR_Rport_KeSOCR_Cnt_CalcInitSOCWithDefaultVals: accessed-parameter=SOCR_Rport.KeSOCR_Cnt_CalcInitSOCWithDefaultVals
          CALPRM_SOCR_Rport_KeSOCR_Cnt_NumberOfCellParal: accessed-parameter=SOCR_Rport.KeSOCR_Cnt_NumberOfCellParal
          CALPRM_SOCR_Rport_KeSOCR_I_CoseToZero: accessed-parameter=SOCR_Rport.KeSOCR_I_CoseToZero
          CALPRM_SOCR_Rport_KeSOCR_I_CoulombsCSC: accessed-parameter=SOCR_Rport.KeSOCR_I_CoulombsCSC
          CALPRM_SOCR_Rport_KeSOCR_I_CurrForCalcTTC_NoCharge: accessed-parameter=SOCR_Rport.KeSOCR_I_CurrForCalcTTC_NoCharge
          CALPRM_SOCR_Rport_KeSOCR_I_LowCurrent: accessed-parameter=SOCR_Rport.KeSOCR_I_LowCurrent
          CALPRM_SOCR_Rport_KeSOCR_I_SOCFixLowCurrent: accessed-parameter=SOCR_Rport.KeSOCR_I_SOCFixLowCurrent
          CALPRM_SOCR_Rport_KeSOCR_I_ThrshldCorrSOCConvrg: accessed-parameter=SOCR_Rport.KeSOCR_I_ThrshldCorrSOCConvrg
          CALPRM_SOCR_Rport_KeSOCR_I_ThrshldLowCurrent: accessed-parameter=SOCR_Rport.KeSOCR_I_ThrshldLowCurrent
          CALPRM_SOCR_Rport_KeSOCR_I_ThrshldSOCCorrection_DE: accessed-parameter=SOCR_Rport.KeSOCR_I_ThrshldSOCCorrection_DE
          CALPRM_SOCR_Rport_KeSOCR_I_ThrshldZeroCurrent: accessed-parameter=SOCR_Rport.KeSOCR_I_ThrshldZeroCurrent
          CALPRM_SOCR_Rport_KeSOCR_Pct_AC_ChgPctCoeff: accessed-parameter=SOCR_Rport.KeSOCR_Pct_AC_ChgPctCoeff
          CALPRM_SOCR_Rport_KeSOCR_Pct_CloseToZeroThreshold: accessed-parameter=SOCR_Rport.KeSOCR_Pct_CloseToZeroThreshold
          CALPRM_SOCR_Rport_KeSOCR_Pct_CorrectedPackSOC_Val: accessed-parameter=SOCR_Rport.KeSOCR_Pct_CorrectedPackSOC_Val
          CALPRM_SOCR_Rport_KeSOCR_Pct_CorrectedScaledSOC_ToCAN: accessed-parameter=SOCR_Rport.KeSOCR_Pct_CorrectedScaledSOC_ToCAN
          CALPRM_SOCR_Rport_KeSOCR_Pct_CustomerPackSOC_MaxVal: accessed-parameter=SOCR_Rport.KeSOCR_Pct_CustomerPackSOC_MaxVal
          CALPRM_SOCR_Rport_KeSOCR_Pct_CustomerPackSOC_Val: accessed-parameter=SOCR_Rport.KeSOCR_Pct_CustomerPackSOC_Val
          CALPRM_SOCR_Rport_KeSOCR_Pct_CustomerPackSOC_minVal: accessed-parameter=SOCR_Rport.KeSOCR_Pct_CustomerPackSOC_minVal
          CALPRM_SOCR_Rport_KeSOCR_Pct_CustomerRealScaledSOC_ToCAN: accessed-parameter=SOCR_Rport.KeSOCR_Pct_CustomerRealScaledSOC_ToCAN
          CALPRM_SOCR_Rport_KeSOCR_Pct_DispSOC_Val: accessed-parameter=SOCR_Rport.KeSOCR_Pct_DispSOC_Val
          CALPRM_SOCR_Rport_KeSOCR_Pct_DisplayPackSOC_MaxVal: accessed-parameter=SOCR_Rport.KeSOCR_Pct_DisplayPackSOC_MaxVal
          CALPRM_SOCR_Rport_KeSOCR_Pct_DisplayPackSOC_minVal: accessed-parameter=SOCR_Rport.KeSOCR_Pct_DisplayPackSOC_minVal
          CALPRM_SOCR_Rport_KeSOCR_Pct_LowSOC1_Reset: accessed-parameter=SOCR_Rport.KeSOCR_Pct_LowSOC1_Reset
          CALPRM_SOCR_Rport_KeSOCR_Pct_LowSOC1_Set: accessed-parameter=SOCR_Rport.KeSOCR_Pct_LowSOC1_Set
          CALPRM_SOCR_Rport_KeSOCR_Pct_LowSOC2_Reset: accessed-parameter=SOCR_Rport.KeSOCR_Pct_LowSOC2_Reset
          CALPRM_SOCR_Rport_KeSOCR_Pct_LowSOC2_Set: accessed-parameter=SOCR_Rport.KeSOCR_Pct_LowSOC2_Set
          CALPRM_SOCR_Rport_KeSOCR_Pct_LowSOC3_Reset: accessed-parameter=SOCR_Rport.KeSOCR_Pct_LowSOC3_Reset
          CALPRM_SOCR_Rport_KeSOCR_Pct_LowSOC3_Set: accessed-parameter=SOCR_Rport.KeSOCR_Pct_LowSOC3_Set
          CALPRM_SOCR_Rport_KeSOCR_Pct_MaxBalDrain: accessed-parameter=SOCR_Rport.KeSOCR_Pct_MaxBalDrain
          CALPRM_SOCR_Rport_KeSOCR_Pct_MaxSOCBeforeVCU_ChrgComplete: accessed-parameter=SOCR_Rport.KeSOCR_Pct_MaxSOCBeforeVCU_ChrgComplete
          CALPRM_SOCR_Rport_KeSOCR_Pct_MaxSlewRateLimitPer100msCorrSOC: accessed-parameter=SOCR_Rport.KeSOCR_Pct_MaxSlewRateLimitPer100msCorrSOC
          CALPRM_SOCR_Rport_KeSOCR_Pct_OvrdValue_BatteryPackSOC: accessed-parameter=SOCR_Rport.KeSOCR_Pct_OvrdValue_BatteryPackSOC
          CALPRM_SOCR_Rport_KeSOCR_Pct_OvrdValue_DisplayPackSOC: accessed-parameter=SOCR_Rport.KeSOCR_Pct_OvrdValue_DisplayPackSOC
          CALPRM_SOCR_Rport_KeSOCR_Pct_OvrdValue_MaxSOC: accessed-parameter=SOCR_Rport.KeSOCR_Pct_OvrdValue_MaxSOC
          CALPRM_SOCR_Rport_KeSOCR_Pct_OvrdValue_MinSOC: accessed-parameter=SOCR_Rport.KeSOCR_Pct_OvrdValue_MinSOC
          CALPRM_SOCR_Rport_KeSOCR_Pct_PackSOCDiff_Val: accessed-parameter=SOCR_Rport.KeSOCR_Pct_PackSOCDiff_Val
          CALPRM_SOCR_Rport_KeSOCR_Pct_SOCChangeThreshold: accessed-parameter=SOCR_Rport.KeSOCR_Pct_SOCChangeThreshold
          CALPRM_SOCR_Rport_KeSOCR_Pct_SOCJumpWarn_Reset: accessed-parameter=SOCR_Rport.KeSOCR_Pct_SOCJumpWarn_Reset
          CALPRM_SOCR_Rport_KeSOCR_Pct_SOCJumpWarn_Set: accessed-parameter=SOCR_Rport.KeSOCR_Pct_SOCJumpWarn_Set
          CALPRM_SOCR_Rport_KeSOCR_Pct_SOCOverWarn_Reset: accessed-parameter=SOCR_Rport.KeSOCR_Pct_SOCOverWarn_Reset
          CALPRM_SOCR_Rport_KeSOCR_Pct_SOCOverWarn_Set: accessed-parameter=SOCR_Rport.KeSOCR_Pct_SOCOverWarn_Set
          CALPRM_SOCR_Rport_KeSOCR_Pct_SOC_SetPointUDS31010F15: accessed-parameter=SOCR_Rport.KeSOCR_Pct_SOC_SetPointUDS31010F15
          CALPRM_SOCR_Rport_KeSOCR_Pct_SOC_ThresholdTTC: accessed-parameter=SOCR_Rport.KeSOCR_Pct_SOC_ThresholdTTC
          CALPRM_SOCR_Rport_KeSOCR_Pct_SlewRateLimitFbackDriving: accessed-parameter=SOCR_Rport.KeSOCR_Pct_SlewRateLimitFbackDriving
          CALPRM_SOCR_Rport_KeSOCR_Pct_SlewRateLimitPer100msAC: accessed-parameter=SOCR_Rport.KeSOCR_Pct_SlewRateLimitPer100msAC
          CALPRM_SOCR_Rport_KeSOCR_Pct_SlewRateLimitPer100msCorrSOC: accessed-parameter=SOCR_Rport.KeSOCR_Pct_SlewRateLimitPer100msCorrSOC
          CALPRM_SOCR_Rport_KeSOCR_Pct_SlewRateLimitPer100msDC: accessed-parameter=SOCR_Rport.KeSOCR_Pct_SlewRateLimitPer100msDC
          CALPRM_SOCR_Rport_KeSOCR_Pct_SlewRateLimitPer100msDriving: accessed-parameter=SOCR_Rport.KeSOCR_Pct_SlewRateLimitPer100msDriving
          CALPRM_SOCR_Rport_KeSOCR_Pct_ThrshldCorrSOC: accessed-parameter=SOCR_Rport.KeSOCR_Pct_ThrshldCorrSOC
          CALPRM_SOCR_Rport_KeSOCR_Pct_TsigBatteryPackSOC_Val: accessed-parameter=SOCR_Rport.KeSOCR_Pct_TsigBatteryPackSOC_Val
          CALPRM_SOCR_Rport_KeSOCR_R_CSCBalancingR: accessed-parameter=SOCR_Rport.KeSOCR_R_CSCBalancingR
          CALPRM_SOCR_Rport_KeSOCR_T_HighTemprChgEnd_DC: accessed-parameter=SOCR_Rport.KeSOCR_T_HighTemprChgEnd_DC
          CALPRM_SOCR_Rport_KeSOCR_U_100PctVoltage: accessed-parameter=SOCR_Rport.KeSOCR_U_100PctVoltage
          CALPRM_SOCR_Rport_KeSOCR_U_CloseToEndOfCharge_AC: accessed-parameter=SOCR_Rport.KeSOCR_U_CloseToEndOfCharge_AC
          CALPRM_SOCR_Rport_KeSOCR_U_CloseToEndOfCharge_DC_1: accessed-parameter=SOCR_Rport.KeSOCR_U_CloseToEndOfCharge_DC_1
          CALPRM_SOCR_Rport_KeSOCR_U_CloseToEndOfCharge_DC_2: accessed-parameter=SOCR_Rport.KeSOCR_U_CloseToEndOfCharge_DC_2
          CALPRM_SOCR_Rport_KeSOCR_U_FullSOCVoltage_Reset: accessed-parameter=SOCR_Rport.KeSOCR_U_FullSOCVoltage_Reset
          CALPRM_SOCR_Rport_KeSOCR_U_FullSOCVoltage_Set: accessed-parameter=SOCR_Rport.KeSOCR_U_FullSOCVoltage_Set
          CALPRM_SOCR_Rport_KeSOCR_U_TTC_StrategyThrshld: accessed-parameter=SOCR_Rport.KeSOCR_U_TTC_StrategyThrshld
          CALPRM_SOCR_Rport_KeSOCR_b_CorrectedPackSOC_Ctrl: accessed-parameter=SOCR_Rport.KeSOCR_b_CorrectedPackSOC_Ctrl
          CALPRM_SOCR_Rport_KeSOCR_b_CustomerPackSOC_Ctrl: accessed-parameter=SOCR_Rport.KeSOCR_b_CustomerPackSOC_Ctrl
          CALPRM_SOCR_Rport_KeSOCR_b_DispSOC_En: accessed-parameter=SOCR_Rport.KeSOCR_b_DispSOC_En
          CALPRM_SOCR_Rport_KeSOCR_b_MinCellCapacityCharge_Ctrl: accessed-parameter=SOCR_Rport.KeSOCR_b_MinCellCapacityCharge_Ctrl
          CALPRM_SOCR_Rport_KeSOCR_b_MinCellCapacityDischarge_Ctrl: accessed-parameter=SOCR_Rport.KeSOCR_b_MinCellCapacityDischarge_Ctrl
          CALPRM_SOCR_Rport_KeSOCR_b_OCV_Disable: accessed-parameter=SOCR_Rport.KeSOCR_b_OCV_Disable
          CALPRM_SOCR_Rport_KeSOCR_b_OvrdCond_AccuCoulombsReset: accessed-parameter=SOCR_Rport.KeSOCR_b_OvrdCond_AccuCoulombsReset
          CALPRM_SOCR_Rport_KeSOCR_b_OvrdCond_BatteryPackCapacity: accessed-parameter=SOCR_Rport.KeSOCR_b_OvrdCond_BatteryPackCapacity
          CALPRM_SOCR_Rport_KeSOCR_b_OvrdCond_BatteryPackSOC: accessed-parameter=SOCR_Rport.KeSOCR_b_OvrdCond_BatteryPackSOC
          CALPRM_SOCR_Rport_KeSOCR_b_OvrdCond_CellCapacityCharge: accessed-parameter=SOCR_Rport.KeSOCR_b_OvrdCond_CellCapacityCharge
          CALPRM_SOCR_Rport_KeSOCR_b_OvrdCond_CellCapacityDischarge: accessed-parameter=SOCR_Rport.KeSOCR_b_OvrdCond_CellCapacityDischarge
          CALPRM_SOCR_Rport_KeSOCR_b_OvrdCond_CellSOCArray_new: accessed-parameter=SOCR_Rport.KeSOCR_b_OvrdCond_CellSOCArray_new
          CALPRM_SOCR_Rport_KeSOCR_b_OvrdCond_DisplayPackSOC: accessed-parameter=SOCR_Rport.KeSOCR_b_OvrdCond_DisplayPackSOC
          CALPRM_SOCR_Rport_KeSOCR_b_OvrdCond_MaxSOC: accessed-parameter=SOCR_Rport.KeSOCR_b_OvrdCond_MaxSOC
          CALPRM_SOCR_Rport_KeSOCR_b_OvrdCond_MinSOC: accessed-parameter=SOCR_Rport.KeSOCR_b_OvrdCond_MinSOC
          CALPRM_SOCR_Rport_KeSOCR_b_OvrdValue_AccuCoulombsReset: accessed-parameter=SOCR_Rport.KeSOCR_b_OvrdValue_AccuCoulombsReset
          CALPRM_SOCR_Rport_KeSOCR_b_PackCapacityCharge_En: accessed-parameter=SOCR_Rport.KeSOCR_b_PackCapacityCharge_En
          CALPRM_SOCR_Rport_KeSOCR_b_PackCapacityDischarge_En: accessed-parameter=SOCR_Rport.KeSOCR_b_PackCapacityDischarge_En
          CALPRM_SOCR_Rport_KeSOCR_b_PackSOCDiff_Ctrl: accessed-parameter=SOCR_Rport.KeSOCR_b_PackSOCDiff_Ctrl
          CALPRM_SOCR_Rport_KeSOCR_b_SOCJumpWarn_Rank_CAN_En: accessed-parameter=SOCR_Rport.KeSOCR_b_SOCJumpWarn_Rank_CAN_En
          CALPRM_SOCR_Rport_KeSOCR_b_SOCJumpWarn_flt_En: accessed-parameter=SOCR_Rport.KeSOCR_b_SOCJumpWarn_flt_En
          CALPRM_SOCR_Rport_KeSOCR_b_SOCLow_Rank_CAN_En: accessed-parameter=SOCR_Rport.KeSOCR_b_SOCLow_Rank_CAN_En
          CALPRM_SOCR_Rport_KeSOCR_b_SOCOverWarn_Rank_CAN_En: accessed-parameter=SOCR_Rport.KeSOCR_b_SOCOverWarn_Rank_CAN_En
          CALPRM_SOCR_Rport_KeSOCR_b_SOCOverWarn_flt_En: accessed-parameter=SOCR_Rport.KeSOCR_b_SOCOverWarn_flt_En
          CALPRM_SOCR_Rport_KeSOCR_b_SOC_SetpointOverrideAck_Ctrl: accessed-parameter=SOCR_Rport.KeSOCR_b_SOC_SetpointOverrideAck_Ctrl
          CALPRM_SOCR_Rport_KeSOCR_b_SOC_SetpointOverrideAck_Val: accessed-parameter=SOCR_Rport.KeSOCR_b_SOC_SetpointOverrideAck_Val
          CALPRM_SOCR_Rport_KeSOCR_b_SOC_low{1..3}_flt_En: accessed-parameter=SOCR_Rport.KeSOCR_b_SOC_low{1..3}_flt_En
          CALPRM_SOCR_Rport_KeSOCR_b_SaveSOCInExtEEP_Ctrl: accessed-parameter=SOCR_Rport.KeSOCR_b_SaveSOCInExtEEP_Ctrl
          CALPRM_SOCR_Rport_KeSOCR_b_SaveSOCInExtEEP_Val: accessed-parameter=SOCR_Rport.KeSOCR_b_SaveSOCInExtEEP_Val
          CALPRM_SOCR_Rport_KeSOCR_b_TimeToCharge_Ctrl: accessed-parameter=SOCR_Rport.KeSOCR_b_TimeToCharge_Ctrl
          CALPRM_SOCR_Rport_KeSOCR_b_TsigAccuCoulombs_Ctrl: accessed-parameter=SOCR_Rport.KeSOCR_b_TsigAccuCoulombs_Ctrl
          CALPRM_SOCR_Rport_KeSOCR_b_TsigBatteryPackSOC_Ctrl: accessed-parameter=SOCR_Rport.KeSOCR_b_TsigBatteryPackSOC_Ctrl
          CALPRM_SOCR_Rport_KeSOCR_b_enable_DE: accessed-parameter=SOCR_Rport.KeSOCR_b_enable_DE
          CALPRM_SOCR_Rport_KeSOCR_k_AccelCoeffAC_ChgSteadySt: accessed-parameter=SOCR_Rport.KeSOCR_k_AccelCoeffAC_ChgSteadySt
          CALPRM_SOCR_Rport_KeSOCR_k_Coeff1_AC: accessed-parameter=SOCR_Rport.KeSOCR_k_Coeff1_AC
          CALPRM_SOCR_Rport_KeSOCR_k_Coeff1_DC: accessed-parameter=SOCR_Rport.KeSOCR_k_Coeff1_DC
          CALPRM_SOCR_Rport_KeSOCR_k_Coeff2_AC: accessed-parameter=SOCR_Rport.KeSOCR_k_Coeff2_AC
          CALPRM_SOCR_Rport_KeSOCR_k_Coeff2_DC: accessed-parameter=SOCR_Rport.KeSOCR_k_Coeff2_DC
          CALPRM_SOCR_Rport_KeSOCR_k_CoeffBias: accessed-parameter=SOCR_Rport.KeSOCR_k_CoeffBias
          CALPRM_SOCR_Rport_KeSOCR_k_CoeffTMax: accessed-parameter=SOCR_Rport.KeSOCR_k_CoeffTMax
          CALPRM_SOCR_Rport_KeSOCR_k_CoeffTMin: accessed-parameter=SOCR_Rport.KeSOCR_k_CoeffTMin
          CALPRM_SOCR_Rport_KeSOCR_k_ContractDiffCorrSOC: accessed-parameter=SOCR_Rport.KeSOCR_k_ContractDiffCorrSOC
          CALPRM_SOCR_Rport_KeSOCR_k_ContractionCoeff: accessed-parameter=SOCR_Rport.KeSOCR_k_ContractionCoeff
          CALPRM_SOCR_Rport_KeSOCR_k_DutyCycleCompensation: accessed-parameter=SOCR_Rport.KeSOCR_k_DutyCycleCompensation
          CALPRM_SOCR_Rport_KeSOCR_k_ExtendNsamplesAck: accessed-parameter=SOCR_Rport.KeSOCR_k_ExtendNsamplesAck
          CALPRM_SOCR_Rport_KeSOCR_k_ExtendSaveToExtEEP: accessed-parameter=SOCR_Rport.KeSOCR_k_ExtendSaveToExtEEP
          CALPRM_SOCR_Rport_KeSOCR_k_MaxAccelCoeffAC_Chg: accessed-parameter=SOCR_Rport.KeSOCR_k_MaxAccelCoeffAC_Chg
          CALPRM_SOCR_Rport_KeSOCR_k_NumOf100msIn30Sec: accessed-parameter=SOCR_Rport.KeSOCR_k_NumOf100msIn30Sec
          CALPRM_SOCR_Rport_KeSOCR_k_SOCJumpWarn_Rank_CAN_Val: accessed-parameter=SOCR_Rport.KeSOCR_k_SOCJumpWarn_Rank_CAN_Val
          CALPRM_SOCR_Rport_KeSOCR_k_SOCJumpWarn_flt_Val: accessed-parameter=SOCR_Rport.KeSOCR_k_SOCJumpWarn_flt_Val
          CALPRM_SOCR_Rport_KeSOCR_k_SOCLow_Rank_CAN_Val: accessed-parameter=SOCR_Rport.KeSOCR_k_SOCLow_Rank_CAN_Val
          CALPRM_SOCR_Rport_KeSOCR_k_SOCOverWarn_Rank_CAN_Val: accessed-parameter=SOCR_Rport.KeSOCR_k_SOCOverWarn_Rank_CAN_Val
          CALPRM_SOCR_Rport_KeSOCR_k_SOCOverWarn_flt_Val: accessed-parameter=SOCR_Rport.KeSOCR_k_SOCOverWarn_flt_Val
          CALPRM_SOCR_Rport_KeSOCR_k_SOC_low{1..3}_flt_Val: accessed-parameter=SOCR_Rport.KeSOCR_k_SOC_low{1..3}_flt_Val
          CALPRM_SOCR_Rport_KeSOCR_min_InitTTC: accessed-parameter=SOCR_Rport.KeSOCR_min_InitTTC
          CALPRM_SOCR_Rport_KeSOCR_min_TTC_Offset: accessed-parameter=SOCR_Rport.KeSOCR_min_TTC_Offset
          CALPRM_SOCR_Rport_KeSOCR_min_TimeToCharge_Val: accessed-parameter=SOCR_Rport.KeSOCR_min_TimeToCharge_Val
          CALPRM_SOCR_Rport_KeSOCR_n_DebncCloseToEndOfCharge: accessed-parameter=SOCR_Rport.KeSOCR_n_DebncCloseToEndOfCharge
          CALPRM_SOCR_Rport_KeSOCR_n_DebncDoSlewRateCorrSOC: accessed-parameter=SOCR_Rport.KeSOCR_n_DebncDoSlewRateCorrSOC
          CALPRM_SOCR_Rport_KeSOCR_n_Num100msInOneMinLess1: accessed-parameter=SOCR_Rport.KeSOCR_n_Num100msInOneMinLess1
          CALPRM_SOCR_Rport_KeSOCR_n_vMinDebounceTime_DE: accessed-parameter=SOCR_Rport.KeSOCR_n_vMinDebounceTime_DE
          CALPRM_SOCR_Rport_KeSOCR_q_NomAccuCoulombs100ms: accessed-parameter=SOCR_Rport.KeSOCR_q_NomAccuCoulombs100ms
          CALPRM_SOCR_Rport_KeSOCR_q_TsigAccuCoulombs_Val: accessed-parameter=SOCR_Rport.KeSOCR_q_TsigAccuCoulombs_Val
          CALPRM_SOCR_Rport_KeSOCR_r_CoulombEfficiency: accessed-parameter=SOCR_Rport.KeSOCR_r_CoulombEfficiency
          CALPRM_SOCR_Rport_KeSOCR_r_RCGain_DE: accessed-parameter=SOCR_Rport.KeSOCR_r_RCGain_DE
          CALPRM_SOCR_Rport_KeSOCR_r_SOCGainScale_DE: accessed-parameter=SOCR_Rport.KeSOCR_r_SOCGainScale_DE
          CALPRM_SOCR_Rport_KeSOCR_r_SOCGain_DE: accessed-parameter=SOCR_Rport.KeSOCR_r_SOCGain_DE
          CALPRM_SOCR_Rport_KeSOCR_r_maxSOCGain_DE: accessed-parameter=SOCR_Rport.KeSOCR_r_maxSOCGain_DE
          CALPRM_SOCR_Rport_KeSOCR_t_FullSOCVoltage_Timer: accessed-parameter=SOCR_Rport.KeSOCR_t_FullSOCVoltage_Timer
          CALPRM_SOCR_Rport_KeSOCR_t_LowSOC_DTCTimer: accessed-parameter=SOCR_Rport.KeSOCR_t_LowSOC_DTCTimer
          CALPRM_SOCR_Rport_KeSOCR_t_SOCJumpWarn_DTCTimer: accessed-parameter=SOCR_Rport.KeSOCR_t_SOCJumpWarn_DTCTimer
          CALPRM_SOCR_Rport_KeSOCR_t_SOCOverWarn_DTCTimer: accessed-parameter=SOCR_Rport.KeSOCR_t_SOCOverWarn_DTCTimer
          CALPRM_SOCR_Rport_KeSOCR_t_SR_SOC: accessed-parameter=SOCR_Rport.KeSOCR_t_SR_SOC
          SCALPRM_KtSOCR_U_SOCOCV_DE_Table: accessed-parameter=KtSOCR_U_SOCOCV_DE_Table, sw-calprm-axis-set={sw-axis-index=1, sw-axis-grouped=ar-parameter=KxSOCR_U_SOCOCV_DE}
          SCALPRM_KtSOCR_U_vMinBasedOnTemp_DE_Table: accessed-parameter=KtSOCR_U_vMinBasedOnTemp_DE_Table, sw-calprm-axis-set={sw-axis-index=1, sw-axis-grouped=ar-parameter=KxSOCR_U_vMinBasedOnTemp_DE}
          SCALPRM_KxSOCR_U_SOCOCV_DE: accessed-parameter=KxSOCR_U_SOCOCV_DE
          SCALPRM_KxSOCR_U_vMinBasedOnTemp_DE: accessed-parameter=KxSOCR_U_vMinBasedOnTemp_DE, sw-calprm-axis-set=sw-axis-individual=sw-variable=VeCSCR_T_AvgCellTempMod.VeCSCR_T_AvgCellTempMod
      5 x swc service dependency:
        SwcNv_NeSOCR_Pct_DisplayPackSOC: assigned-datas=role-based-data-assignment={role=ramBlock, used-pim=NeSOCR_Pct_DisplayPackSOC}
          service-needs:
            nv block needs SwcNv_NeSOCR_Pct_DisplayPackSOC: restore-at-start=true, store-at-shutdown=true
        SwcNv_NaSOCR_Pct_CellSOC: assigned-datas=role-based-data-assignment={role=ramBlock, used-pim=NaSOCR_Pct_CellSOC}
          service-needs:
            nv block needs SwcNv_NaSOCR_Pct_CellSOC: restore-at-start=true, store-at-shutdown=true
        SwcNv_NeSOCR_Pct_CorrectedPackSOC: assigned-datas=role-based-data-assignment={role=ramBlock, used-pim=NeSOCR_Pct_CorrectedPackSOC}
          service-needs:
            nv block needs SwcNv_NeSOCR_Pct_CorrectedPackSOC: restore-at-start=true, store-at-shutdown=true
        SwcNv_NeSOCR_Pct_PackSOCDiff: assigned-datas=role-based-data-assignment={role=ramBlock, used-pim=NeSOCR_Pct_PackSOCDiff}
          service-needs:
            nv block needs SwcNv_NeSOCR_Pct_PackSOCDiff: restore-at-start=true, store-at-shutdown=true
        SwcNv_NeSOCR_b_NVMEnable_CellSOC: assigned-datas=role-based-data-assignment={role=ramBlock, used-pim=NeSOCR_b_NVMEnable_CellSOC}
          service-needs:
            nv block needs SwcNv_NeSOCR_b_NVMEnable_CellSOC: restore-at-start=true, store-at-shutdown=true
      shared-parameters:
        4 x parameter data prototype, all with sw-calibration-access=READ-WRITE:
          KtSOCR_U_SOCOCV_DE_Table: category=CURVE, type=Appl_KtSOCR_U_SOCOCV_DE_Table, init-value=constant-reference={short-label=KtSOCR_U_SOCOCV_DE_Table, constant=KtSOCR_U_SOCOCV_DE_Table}
          KtSOCR_U_vMinBasedOnTemp_DE_Table: category=CURVE, type=Appl_KtSOCR_U_vMinBasedOnTemp_DE_Table, init-value=constant-reference={short-label=KtSOCR_U_vMinBasedOnTemp_DE_Table, constant=KtSOCR_U_vMinBasedOnTemp_DE_Table}
          KxSOCR_U_SOCOCV_DE: category=COM_AXIS, type=Appl_KxSOCR_U_SOCOCV_DE, init-value=constant-reference={short-label=KxSOCR_U_SOCOCV_DE, constant=KxSOCR_U_SOCOCV_DE}
          KxSOCR_U_vMinBasedOnTemp_DE: category=COM_AXIS, type=Appl_KxSOCR_U_vMinBasedOnTemp_DE, init-value=constant-reference={short-label=KxSOCR_U_vMinBasedOnTemp_DE, constant=KxSOCR_U_vMinBasedOnTemp_DE}
